# max32690 register map
Vendor: Maxim-Integrated; Series: ARMCM4; File version: 1.0
CPU: CM4 r2p1, little endian, MPU, FPU, 3 interrupt priority bits
Registers are 32-bit, read-write, reset 0x0 unless marked. A register's access mark holds for its fields unless they carry their own. Offsets are from the block's base; [hi:lo] are bit positions; 'fields as' and 'values as' point back to an identical list.

## AESKEYS — AES Key Registers.
Base 0x40005000
0x00 KEY0 128-bit (reset mask 0xFFFFFFFF) — AES Key 0.
0x10 KEY1 128-bit (reset mask 0xFFFFFFFF) — AES Key 1.

## EMCC — External Memory Cache Controller Registers.
Base 0x40033000
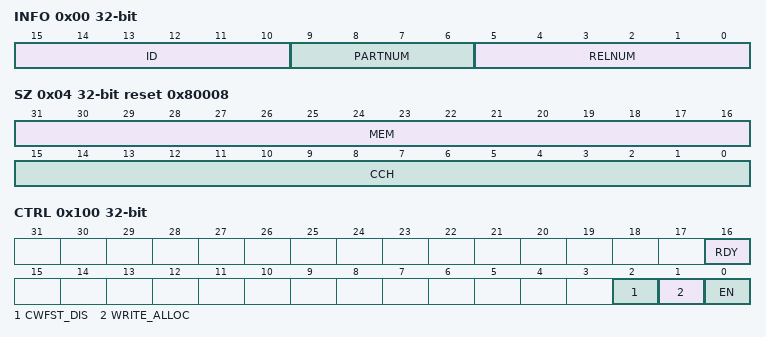
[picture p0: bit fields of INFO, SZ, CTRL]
0x00 INFO ro — Cache ID Register.
  [15:10] ID — Cache ID. This field reflects the value of the C_ID_CACHEID configuration parameter.
  [9:6] PARTNUM — Part Number. This field reflects the value of C_ID_PART_NUMBER configuration parameter.
  [5:0] RELNUM — Release Number. Identifies the RTL release version.
0x04 SZ ro reset 0x80008 — Memory Configuration Register.
  [31:16] MEM — Main Memory Size. Indicates the total size, in units of 128 Kbytes, of code memory accessible to the cache controller.
  [15:0] CCH — Cache Size. Indicates total size in Kbytes of cache.
0x100 CTRL — Cache Control and Status Register.
  [16] RDY — Cache Ready flag. Cleared by hardware when at any time the cache as a whole is invalidated (including a system reset). When this bit is 0, the cache is effectively in bypass mode (instruction fetches will come from main memory or from the line fill buffer). Set by hardware when the invalidate operation is complete and the cache is ready.
    0=notReady; 1=ready
  [2] CWFST_DIS — Critical word first and streaming disable. This bit only writeable while the cache is disabled.
    1=dis (Critical word first and streaming disabled.); 0=en (Critical word first and streaming enabled.)
  [1] WRITE_ALLOC — Write Allocate Enable. This bit only writable while the cache is disabled.
    0=dis (Write-no-allocate.); 1=en (Write-allocate enabled.)
  [0] EN — Cache Enable. Controls whether the cache is bypassed or is in use. Changing the state of this bit will cause the instruction cache to be flushed and its contents invalidated.
    0=dis (Cache Bypassed. Instruction data is stored in the line fill buffer but is not written to main cache memory array.); 1=en (Cache Enabled.)
0x700 INVALIDATE — Invalidate All Cache Contents. Any time this register location is written (regardless of the data value), the cache controller immediately begins invalidating the entire contents of the cache memory. The cache will be in bypass mode until the invalidate operation is complete. System software can examine the Cache Ready bit (CACHE_CTRL.CACHE_RDY) to determine when the invalidate operation is complete. Note that it is not necessary to disable the cache controller prior to beginning this operation. Reads from this register always return 0.
  [31:0] IA — Invalidate all cache contents.

## FCR — Function Control Register.
Base 0x40000800
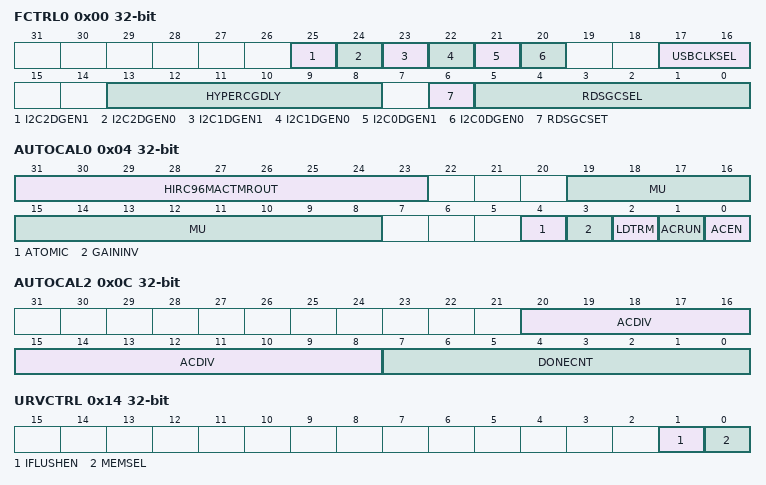
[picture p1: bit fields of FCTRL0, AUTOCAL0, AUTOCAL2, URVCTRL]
0x00 FCTRL0 — Function Control 0.
  [25] I2C2DGEN1 — I2C2 SCL Pad Deglitcher enable.
    0=dis (Deglitcher disabled.); 1=en (Deglitcher enabled.)
  [24] I2C2DGEN0 — I2C2 SDA Pad Deglitcher enable.
    0=dis (Deglitcher disabled.); 1=en (Deglitcher enabled.)
  [23] I2C1DGEN1 — I2C1 SCL Pad Deglitcher enable.
    0=dis (Deglitcher disabled.); 1=en (Deglitcher enabled.)
  [22] I2C1DGEN0 — I2C1 SDA Pad Deglitcher enable.
    0=dis (Deglitcher disabled.); 1=en (Deglitcher enabled.)
  [21] I2C0DGEN1 — I2C0 SCL Pad Deglitcher enable.
    0=dis (Deglitcher disabled.); 1=en (Deglitcher enabled.)
  [20] I2C0DGEN0 — I2C0 SDA Pad Deglitcher enable.
    0=dis (Deglitcher disabled.); 1=en (Deglitcher enabled.)
  [17:16] USBCLKSEL — USB Core Clock Select.
  [13:8] HYPERCGDLY — Hyperbus Clock Generator Delay.
  [6] RDSGCSET — Hyperbus RDS Set.
  [5:0] RDSGCSEL — Hyperbys RDS Gray Code Select.
0x04 AUTOCAL0 — Automatic Calibration 0.
  [31:23] HIRC96MACTMROUT — HIRC96M Trim Value.
  [19:8] MU — MU value.
  [4] ATOMIC — Atomic mode.
    0=not (Not Running.); 1=run (Running.)
  [3] GAININV — Invert Gain.
    0=not (Not Running.); 1=run (Running.)
  [2] LDTRM — Load Trim.
  [1] ACRUN — Autocalibration Run.
    0=not (Not Running.); 1=run (Running.)
  [0] ACEN — Auto-calibration Enable.
    0=dis (Disabled.); 1=en (Enabled.)
0x08 AUTOCAL1 — Automatic Calibration 1.
  [8:0] INITTRM — Initial Trim Setting.
0x0C AUTOCAL2 — Automatic Calibration 2
  [20:8] ACDIV — Auto-callibration Div Setting.
  [7:0] DONECNT — Auto-callibration Done Counter Setting.
0x10 URVBOOTADDR — RISC-V Boot Address.
0x14 URVCTRL — RISC-V Control Register.
  [1] IFLUSHEN — URV instruction flush enable.
  [0] MEMSEL — RAM2, RAM3 exclusive ownership.
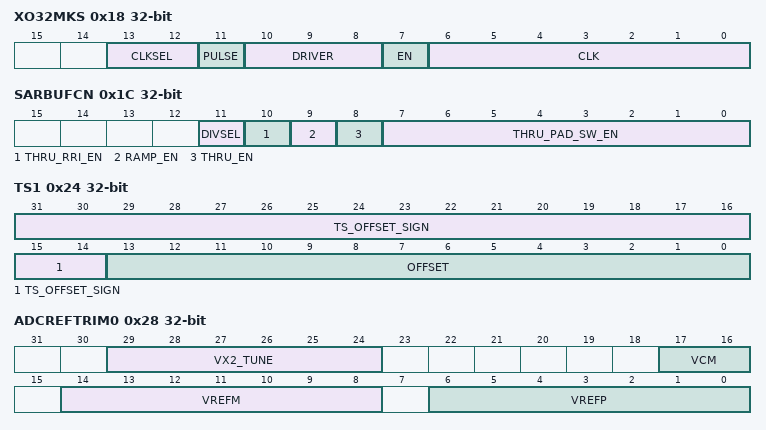
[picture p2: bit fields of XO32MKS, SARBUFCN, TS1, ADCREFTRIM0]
0x18 XO32MKS — RISC-V Control Register.
  [13:12] CLKSEL — Kick Start XO Clock Select
    0=none (No kick start clock.); 1=Test Clock in P1.2 (TMR3[22]=1); 2=ISO (Internal secondary oscilator); 3=IPO (Internal Primary Oscilator)
  [11] PULSE — Kick Start XO 2X Pulse
  [10:8] DRIVER — Kick Start XO Driver
  [7] EN — Kick Start XO Enable
  [6:0] CLK — Kick Start XO Counter Setting
0x1C SARBUFCN
  [11] DIVSEL, [10] THRU_RRI_EN, [9] RAMP_EN, [8] THRU_EN, [7:0] THRU_PAD_SW_EN
0x20 TS0 — Temp Sensor trim0
  [11:0] GAIN — Unsigned gain for temp sensor normalization Temp degrees C = (ADC result * TS_GAIN) + TS_OFFSET.
0x24 TS1 — Temp Sensor trim1
  [31:14] TS_OFFSET_SIGN — Sign extension of TS_OFFSET[13:0]
  [13:0] OFFSET — Signed gain for temp sensor normalization Temp degrees C = (ADC result * TS_GAIN) + TS_OFFSET.
0x28 ADCREFTRIM0 — Temp Sensor trim1
  [29:24] VX2_TUNE — Controls tuning capacitor in fine DAC (offset binary)
  [17:16] VCM — Trimming code for VCM output of reference buffer
  [14:8] VREFM — Trimming code for VREFM output of reference buffer
  [6:0] VREFP — Trimming code for VREFP output of reference buffer
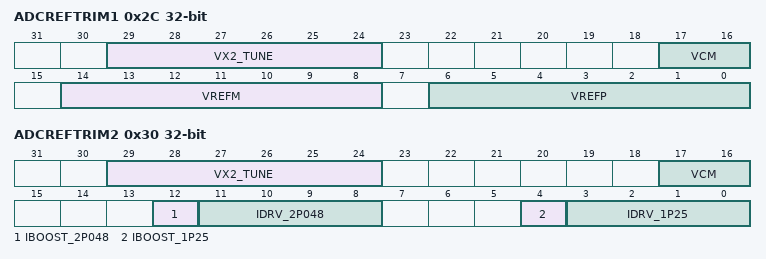
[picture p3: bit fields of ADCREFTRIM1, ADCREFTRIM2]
0x2C ADCREFTRIM1 — Temp Sensor trim1
  fields as ADCREFTRIM0
0x30 ADCREFTRIM2 — Temp Sensor trim1
  [29:24] VX2_TUNE — Controls tuning capacitor in fine DAC (offset binary)
  [17:16] VCM — Trimming code for VCM output of reference buffer
  [12] IBOOST_2P048 — Trimming value for extra drive current in reference buffer outputs. 2.048V
  [11:8] IDRV_2P048 — Trimming code for reference buffer drive strength. 2.048V
  [4] IBOOST_1P25 — Trimming value for extra drive current in reference buffer outputs. 2.048V
  [3:0] IDRV_1P25 — Trimming code for reference buffer drive strength. 1.25V
